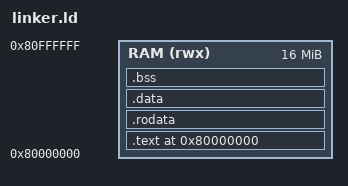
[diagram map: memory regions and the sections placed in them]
OUTPUT_ARCH(riscv)
ENTRY(_start)

MEMORY {
    RAM (rwx) : ORIGIN = 0x80000000, LENGTH = 16M
}

SECTIONS {
    . = 0x80000000;

    .text : ALIGN(4) {
        KEEP(*(.text.entry))
        KEEP(*(.text.trap))
        *(.text .text.*)
    } > RAM

    .rodata : ALIGN(4) {
        *(.rodata .rodata.*)
        *(.srodata .srodata.*)
    } > RAM

    .data : ALIGN(4) {
        *(.data .data.*)
        *(.sdata .sdata.*)
    } > RAM

    .bss : ALIGN(4) {
        __bss_start = .;
        *(.bss .bss.*)
        *(.sbss .sbss.*)
        *(COMMON)
        __bss_end = .;
    } > RAM

    . = ALIGN(16);
    __heap_start = .;
    __heap_end = ORIGIN(RAM) + LENGTH(RAM) - 64K;
    __stack_top = ORIGIN(RAM) + LENGTH(RAM);
}
